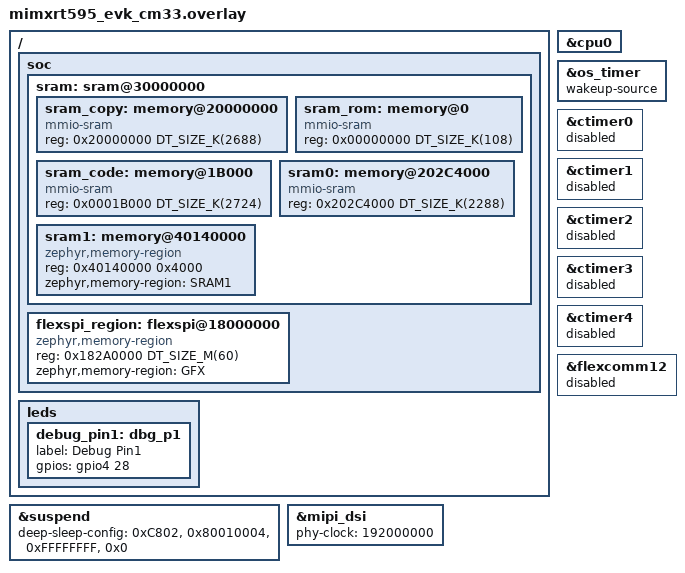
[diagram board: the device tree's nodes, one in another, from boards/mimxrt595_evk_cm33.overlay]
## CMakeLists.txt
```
# SPDX-License-Identifier: Apache-2.0

cmake_minimum_required(VERSION 3.20.0)

# If SMARTWATCH_IN_RAM_APP is defined, pull in dts and kconfig overlays for
# this feature
if (DEFINED SMARTWATCH_IN_RAM_APP)
	list(APPEND EXTRA_DTC_OVERLAY_FILE smartwatch_ram.overlay)
	list(APPEND EXTRA_CONF_FILE smartwatch_ram.conf)
	# Manually cache variable, so CMake does not warn it it unused
	set(SMARTWATCH_IN_RAM_APP CACHE BOOL "Smartwatch app in RAM")
endif()

# If SMARTWATCH_REDUCE_RAM is defined, pull in dts and kconfig overlays for
# this feature
if (DEFINED SMARTWATCH_REDUCE_RAM)
	list(APPEND EXTRA_DTC_OVERLAY_FILE reduce_ram.overlay)
	list(APPEND EXTRA_CONF_FILE reduce_ram.conf)
	# Manually cache variable, so CMake does not warn it it unused
	set(SMARTWATCH_REDUCE_RAM CACHE BOOL "Reduce SRAM utilization")
endif()

set(SHIELD g1120b0mipi)

find_package(Zephyr REQUIRED HINTS $ENV{ZEPHYR_BASE})

# Include VGLite port
add_subdirectory(vglite-port)

FILE(GLOB app_sources src/*.c)

if (DEFINED CONFIG_SMARTWATCH_PVT_SENSOR)
        set(LIB_DIR  ${CMAKE_CURRENT_SOURCE_DIR}/../../../modules/hal/appswpacks-dvs-pvt-sensor/dvs_pvt_sensor/app)
        add_library(libpvt STATIC IMPORTED GLOBAL)
        set_target_properties(libpvt PROPERTIES IMPORTED_LOCATION ${LIB_DIR}/evkmimxrt595/pvt_lib/libpvt.a)
        target_link_libraries(app PUBLIC libpvt)
        include_directories(app ${LIB_DIR}/common/pvt_lib)
        include_directories(app ${LIB_DIR}/evkmimxrt595/pvt_lib)
        include_directories(app src/PVT)
        FILE(GLOB pvt_sources src/PVT/*.c)
        list(APPEND app_sources ${pvt_sources})
      endif()

if (DEFINED CONFIG_LVGL)
        project(lvgl)

 	set(UI_PATH UI_SW)

        include_directories(app src/${UI_PATH})
        include_directories(app src/${UI_PATH}/custom)
        include_directories(app src/${UI_PATH}/generated)
        include_directories(app src/${UI_PATH}/generated/guider_customer_fonts)
        include_directories(app src/${UI_PATH}/generated/guider_fonts)
        include_directories(app src/${UI_PATH}/generated/images)

	FILE(GLOB gfx_sources src/${UI_PATH}/*.c src/${UI_PATH}/generated/*.c src/${UI_PATH}/generated/guider_fonts/*.c src/${UI_PATH}/generated/guider_customer_fonts/*.c src/${UI_PATH}/generated/images/*.c src/${UI_PATH}/custom/*.c)
	list(APPEND app_sources ${gfx_sources})

  add_library(libLogos STATIC IMPORTED GLOBAL)
  set_target_properties(libLogos PROPERTIES IMPORTED_LOCATION
      ${CMAKE_CURRENT_SOURCE_DIR}/src/${UI_PATH}/generated/images/logos_lib/libLogos.a)
  target_link_libraries(app PUBLIC libLogos)
endif()

# Relocate GFX data into a FlexSPI region. This is required because not
# all assets for the demo can fit in SRAM.
set(gfx_path src/${UI_PATH})
if(NOT CONFIG_SMARTWATCH_IN_RAM_DIGITAL_SCREEN)
  zephyr_code_relocate(FILES
    ${gfx_path}/generated/images/lv_font_Montserrat_Light_40.c
    ${gfx_path}/generated/images/ui_font_medium_font.c
    ${gfx_path}/generated/images/ui_font_number_bold.c
    ${gfx_path}/generated/images/ui_font_number_light.c
    ${gfx_path}/generated/images/ui_img_icn_flash_png.c
    ${gfx_path}/generated/images/ui_img_icn_message_png.c
    ${gfx_path}/generated/images/ui_img_icn_sport_png.c
    ${gfx_path}/generated/images/ui_img_icn_weather_1_png.c
    ${gfx_path}/generated/images/ui_img_img_bg_digital_png.c
    ${gfx_path}/generated/images/ui_img_img_clock_shadow_png.c
    ${gfx_path}/generated/images/ui_img_img_menu_png.c
    ${gfx_path}/generated/images/ui_img_img_nxp_png.c
    ${gfx_path}/generated/images/ui_img_text_message_png.c
    ${gfx_path}/generated/images/ui_img_text_sport_png.c
    LOCATION GFX_RODATA NOCOPY)
endif()

zephyr_code_relocate(FILES
  ${gfx_path}/generated/images/ui_font_big_font.c
  ${gfx_path}/generated/images/ui_font_small_font.c
  ${gfx_path}/generated/images/ui_img_icn_home_png.c
  ${gfx_path}/generated/images/ui_img_icn_small_burn_png.c
  ${gfx_path}/generated/images/ui_img_icn_small_pos_png.c
  ${gfx_path}/generated/images/ui_img_icn_small_pulse_png.c
  ${gfx_path}/generated/images/ui_img_icn_small_time_png.c
  ${gfx_path}/generated/images/ui_img_icn_small_weather_1_png.c
  ${gfx_path}/generated/images/ui_img_icn_small_weather_2_png.c
  ${gfx_path}/generated/images/ui_img_icn_small_weather_3_png.c
  ${gfx_path}/generated/images/ui_img_img_arrow_left_png.c
  ${gfx_path}/generated/images/ui_img_img_arrow_right_png.c
  ${gfx_path}/generated/images/ui_img_icn_audio_back_png.c
  ${gfx_path}/generated/images/ui_img_icn_audio_next_png.c
  ${gfx_path}/generated/images/ui_img_icn_audio_play_png.c
  ${gfx_path}/generated/images/ui_img_icn_audio_rnd_png.c
  ${gfx_path}/generated/images/ui_img_img_audio_album_png.c
  ${gfx_path}/generated/images/ui_img_img_bg_2_png.c
  ${gfx_path}/generated/images/ui_img_img_bg_analog_png.c
  ${gfx_path}/generated/images/ui_img_img_bg_health_png.c
  ${gfx_path}/generated/images/ui_img_img_clockwise_hour_png.c
  ${gfx_path}/generated/images/ui_img_img_clockwise_min_png.c
  ${gfx_path}/generated/images/ui_img_img_clockwise_sec_png.c
  ${gfx_path}/generated/images/ui_img_img_cloud_png.c
  ${gfx_path}/generated/images/ui_img_img_ekg_png.c
  ${gfx_path}/generated/images/ui_img_img_header_bg_png.c
  ${gfx_path}/generated/images/ui_img_img_header_bg_shadow_png.c
  ${gfx_path}/generated/images/ui_img_img_heart_png.c
  ${gfx_path}/generated/images/ui_img_img_nxp_logo_big_png.c
  ${gfx_path}/generated/images/ui_img_img_pause_png.c
  ${gfx_path}/generated/images/ui_img_img_squareline_png.c
  ${gfx_path}/generated/images/ui_img_img_sun_png.c
  ${gfx_path}/generated/images/ui_img_text_audio_volume_png.c
  ${gfx_path}/generated/images/ui_img_text_home_png.c
  ${gfx_path}/generated/images/ui_img_text_select_png.c
  ${gfx_path}/generated/images/ui_img_text_start_stop_png.c
  ${gfx_path}/generated/images/_coursewrkwavesfeb_dribbble_392x392.c
  ${gfx_path}/generated/images/_icn_weather_2_41x38.c
  ${gfx_path}/generated/images/_icn_weather_3_41x38.c
  ${gfx_path}/generated/images/_img_clockwise_hourLP_18x98.c
  ${gfx_path}/generated/images/_img_clockwise_minLP_18x157.c
  ${gfx_path}/generated/images/_img_clockwise_secLP_31x180.c
  ${gfx_path}/generated/images/_img_cloud_2_586x147.c
  ${gfx_path}/generated/images/_img_nxpLP_65x23.c
  ${gfx_path}/generated/images/_Zephyr_RTOS_logo_118x57.c
  LOCATION GFX_RODATA NOCOPY)

# Relocate SDMA firmware back to flash, as the driver copies it to RAM
zephyr_code_relocate(FILES
  ${ZEPHYR_BASE}/../modules/hal/nxp/mcux/mcux-sdk/drivers/smartdma/fsl_smartdma.c
  LOCATION GFX_RODATA NOCOPY)

# The following snippet modifies the objcopy relocate command the build system
# will run to relocate the built ELF file, so that the GFX section will not
# be relocated. When combined with the zephyr_code_relocate macro, this will
# result in the GFX RODATA section being relocated to flash, and not
# affecting the total image size. This means that the ROM will not attempt
# to copy the GFX data to SRAM, and it can be read directly from FlexSPI.
if(CONFIG_BUILD_OUTPUT_ADJUST_LMA)
  math(EXPR adjustment "${CONFIG_BUILD_OUTPUT_ADJUST_LMA}" OUTPUT_FORMAT DECIMAL)
  set(excluded_sections
	  ".gfx_rodata_reloc")
  set(lma_adjust --change-section-lma *+${adjustment})
  foreach(section ${excluded_sections})
    list(APPEND lma_adjust --change-section-lma !${section}+1)
  endforeach()
  set_property(TARGET bintools PROPERTY elfconvert_flag_lma_adjust ${lma_adjust})
endif()

target_sources(app PRIVATE ${app_sources})
```

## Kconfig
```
# Copyright 2023 NXP
# SPDX-License-Identifier: Apache-2.0

# Source Kconfig file from VGLite port
rsource "vglite-port/Kconfig"

# Config options for SmartWatch app

config SMARTWATCH_IN_RAM_APP
	bool "Move all code and non-LVGL rodata to internal SRAM"
	default n

config SMARTWATCH_IN_RAM_DIGITAL_SCREEN
	bool "Place all data and assets for the Digital Watch screen in SRAM"
	default n
	depends on LVGL && SMARTWATCH_IN_RAM_APP

config SMARTWATCH_REDUCE_RAM
	bool "minimizes SRAM used by application"
	default n

config SMARTWATCH_PVT_SENSOR
	bool "Enable PVT Sensor to reduce VDDCORE voltage and reduce power"
	default n
	select EVENTS
	# prebuilt lippvt.a uses VFP arguments, need to build app with CONFIG_FPU
	select FPU

config SMARTWATCH_FOR_MEASUREMENTS
	bool "When measuring power consumption, helps keep measurements consistent"
	default n

if SMARTWATCH_IN_RAM_APP

	FLEXSPI_PATH:=$(dt_nodelabel_path,flexspi)
	SRAM_PATH:=$(dt_nodelabel_path,sram_code)
	FLEXSPI_BASE:=$(dt_node_reg_addr_hex,$(FLEXSPI_PATH),1)
	SRAM_BASE:=$(dt_node_reg_addr_hex,$(SRAM_PATH))

	# Adjust the LMA of the output file to reside in FlexSPI, so that the
	# image will be loaded there. The ROM bootloader will then load the
	# application into internal SRAM
	config BUILD_OUTPUT_ADJUST_LMA
		default "$(FLEXSPI_BASE)-$(SRAM_BASE)"

endif # SMARTWATCH_IN_RAM_APP

config LV_MEM_SIZE_KILOBYTES
	default 64 if SMARTWATCH_REDUCE_RAM
	default 128

config VGLITE_HEAP_SIZE
	default 0x8000 if SMARTWATCH_REDUCE_RAM

source "Kconfig.zephyr"
```

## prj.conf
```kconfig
CONFIG_MAIN_STACK_SIZE=4096
CONFIG_IDLE_STACK_SIZE=1024
CONFIG_SYSTEM_WORKQUEUE_STACK_SIZE=2048
CONFIG_BUILD_OUTPUT_HEX=y
CONFIG_DISPLAY=y
CONFIG_FLEXCOMM0_CLK_SRC_FRO=y
CONFIG_MIPI_DPHY_CLK_SRC_FRO=y

# LVGL
CONFIG_LVGL=y
CONFIG_LV_DISP_DEF_REFR_PERIOD=17
CONFIG_LV_DISP_ROT_MAX_BUF=40960
CONFIG_LV_Z_MEM_POOL_NUMBER_BLOCKS=8
#CONFIG_LV_MEM_CUSTOM=y
CONFIG_LV_USE_LOG=y
CONFIG_LV_USE_LABEL=y
CONFIG_LV_USE_BTN=y
CONFIG_LV_USE_IMG=y
#CONFIG_LV_USE_ARC=y
CONFIG_LV_FONT_MONTSERRAT_14=y
CONFIG_LV_FONT_FMT_TXT_LARGE=y
CONFIG_LV_USE_GPU_NXP_VG_LITE=y
CONFIG_LV_Z_DOUBLE_VDB=n
CONFIG_LV_Z_FLUSH_THREAD=n

#Shell
CONFIG_SHELL=y

# Power management
CONFIG_PM=y
CONFIG_PM_DEVICE=y
CONFIG_SMARTWATCH_PVT_SENSOR=n

# Log
CONFIG_LOG=n
#CONFIG_DISPLAY_LOG_LEVEL_ERR=y

# Debugging and System View
#CONFIG_NO_OPTIMIZATIONS=y - Display does not work if optimizations disabled
#CONFIG_DEBUG_OPTIMIZATIONS=y
CONFIG_DEBUG_THREAD_INFO=y
CONFIG_INIT_STACKS=y
CONFIG_THREAD_STACK_INFO=y
CONFIG_TRACING=y
CONFIG_TRACING_THREAD_STACK_SIZE=2048

# Optimize Power by moving from flash to SRAM
CONFIG_SMARTWATCH_IN_RAM_DIGITAL_SCREEN=n

# Make sure we always can access flexSPI data
CONFIG_FLASH_MCUX_FLEXSPI_XIP=y

# For taking power measurements, to keep more consistent
CONFIG_SMARTWATCH_FOR_MEASUREMENTS=n
```

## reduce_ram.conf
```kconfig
# Copyright 2023 NXP
# SPDX-License-Identifier: Apache-2.0

CONFIG_SMARTWATCH_REDUCE_RAM=y
```

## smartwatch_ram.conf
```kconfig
# Copyright 2023 NXP
# SPDX-License-Identifier: Apache-2.0

CONFIG_SMARTWATCH_IN_RAM_APP=y
```

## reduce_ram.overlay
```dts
/*
 * Copyright 2023-2024 NXP
 *
 * SPDX-License-Identifier: Apache-2.0
 */

/ {
	soc {
		sram: sram@30000000 {
			sram0: memory@202C4000 {
				/* When SMARTWATCH_REDUCE_RAM=y, can 
				 * reduce RAM size
				 */
				reg = < 0x202C4000 DT_SIZE_K(1264) >;
			};
			/* When SMARTWATCH_REDUCE_RAM=y, remaining SRAM
			 * is powered off to improve battery life
			 */
			sram_unpowered: memory@20400000 {
				compatible = "mmio-sram";
				reg = < 0x20400000 DT_SIZE_M(1) >;
			};
		};
	};
};

&suspend {
	/* Keep Powered in Deep Sleep */
	deep-sleep-config =
		/* PDSLEEPCFG0: RBBs, LPOSC, PMIC_MODE=1 */
		< 0xC802 >,
		/* PDSLEEPCFG1: SRAM_SLEEP, SDMA_SRAM, FlexSPI0_SRAM */
		< 0x80010004 >,
		/* PDSLEEPCFG2: power off some of the SRAM */
		< 0x0FFFFFF9 >,
		/* PDSLEEPCFG3: no System SRAM peripheries */
		< 0x0 >;
};
```

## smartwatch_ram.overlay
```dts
/*
 * Copyright 2023, NXP
 *
 * SPDX-License-Identifier: Apache-2.0
 */

/ {
	/*
	 * Move flash region to SRAM, so that code and rodata will be linked
	 * there instead of into FlexSPI. Note some large LVGL assets will
	 * still be located in the flash region.
	 */
	chosen {
		zephyr,flash = &sram_code;
	};
};
```

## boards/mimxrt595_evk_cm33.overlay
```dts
/*
 * Copyright 2023-2024 NXP
 *
 * SPDX-License-Identifier: Apache-2.0
 */

/ {
	soc {
		/* Use all 5MB of SRAM */
		/delete-node/ sram@30018000;
		sram: sram@30000000 {
			ranges = <
				0x00000000 0x10000000 DT_SIZE_M(5)
				0x20000000 0x30000000 DT_SIZE_M(5) >;
			#address-cells = < 0x1 >;
			#size-cells = < 0x1 >;
			sram_copy: memory@20000000 {
				compatible = "mmio-sram";
				reg = < 0x20000000 DT_SIZE_K(2688) >;
			};
			/*
			 * The first 0x1BFFF bytes of SRAM are reserved
			 * for the ROM, and it will not perform a Load-to-RAM.
			 * boot into that location. Note that the ROM headers
			 * take up 0x1000 bytes, so we can
			 * start the image location at 0x1B000.
			 */
			sram_rom: memory@0 {
				compatible = "mmio-sram";
				reg = < 0x00000000 DT_SIZE_K(108) >;
			};
			sram_code: memory@1B000 {
				compatible = "mmio-sram";
				reg = < 0x0001B000 DT_SIZE_K(2724) >;
			};
			sram0: memory@202C4000 {
				compatible = "mmio-sram";
				reg = < 0x202C4000 DT_SIZE_K(2288) >;
			};
			sram1: memory@40140000 {
				compatible = "zephyr,memory-region", "mmio-sram";
				reg = < 0x40140000 0x4000 >;
				zephyr,memory-region = "SRAM1";
			};
		};

		flexspi_region: flexspi@18000000 {
			compatible = "zephyr,memory-region";
			reg = <0x182A0000 DT_SIZE_M(60)>;
			zephyr,memory-region = "GFX";
		};
	};

	leds {
		/* For debugging:
		*	- CLKOUT, J18-p1, P2_29
		*	- dbg_p1, J28-p1, P4_28
		*/
		debug_pin1: dbg_p1 {
			label = "Debug Pin1";
			gpios = <&gpio4 28 GPIO_ACTIVE_HIGH>;
			status = "okay";
		};
	};
};

&cpu0 {
	/* Removes Deep Sleep (Suspend) option from PM subsystem */
	//cpu-power-states = < &idle >;
};

&suspend {
	/* Keep Powered in Deep Sleep */
	deep-sleep-config =
		/* PDSLEEPCFG0: RBBs, LPOSC, PMIC_MODE=1 */
		< 0xC802 >,
		/* PDSLEEPCFG1: SRAM_SLEEP, SDMA_SRAM, FlexSPI0_SRAM */
		< 0x80010004 >,
		/* PDSLEEPCFG2: keep all SRAM powered */
		< 0xFFFFFFFF >,
		/* PDSLEEPCFG3: no System SRAM peripheries */
		< 0x0 >;
};

&os_timer {
	status = "okay";
	wakeup-source;
};

/* Disable the unused CTimers */
&ctimer0 {
	status = "disabled";
};
&ctimer1 {
	status = "disabled";
};
&ctimer2 {
	status = "disabled";
};
&ctimer3 {
	status = "disabled";
};
&ctimer4 {
	status = "disabled";
};

&mipi_dsi {
	phy-clock = < 192000000 >;
};

/* Disable Flexcomm12.  PIO4_30 input has high leakage on EVK */
&flexcomm12 {
	status = "disabled";
};
```

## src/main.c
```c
/*
 * Copyright 2023-2024 NXP
 *
 * SPDX-License-Identifier: Apache-2.0
 */

#include <zephyr/device.h>
#include <zephyr/devicetree.h>
#include <zephyr/drivers/gpio.h>
#include <zephyr/kernel.h>
#include "board.h"
#include "fsl_power.h"

#ifdef CONFIG_LOG
	#define LOG_LEVEL CONFIG_LOG_DEFAULT_LEVEL
	#include <zephyr/logging/log.h>
	LOG_MODULE_REGISTER(app);
#else
	#undef  LOG_ERR
	#define LOG_ERR(...)
#endif

#ifdef CONFIG_PM
	#include <zephyr/pm/pm.h>
#endif

/*******************************************************************************
 * Definitions
 ******************************************************************************/
/* for threads */
#define THREAD_STACKSIZE	4096
#define THREAD_PRIORITY_PVT	1	/* PVT Sensor thread highest priority */
#define THREAD_PRIORITY_LVGL	2

/*******************************************************************************
 * Global Variables
 ******************************************************************************/

/*******************************************************************************
 * Prototypes
 ******************************************************************************/

#ifdef CONFIG_LVGL
	/* lvgl_thread */
	extern void lvgl_thread(void *dummy1, void *dummy2, void *dummy3);

	K_THREAD_STACK_DEFINE(lvgl_thread_stack_area, THREAD_STACKSIZE);
	static struct k_thread lvgl_thread_data;
#endif

#ifdef CONFIG_SMARTWATCH_PVT_SENSOR
	#include "PVT_Sensor.h"

	K_THREAD_STACK_DEFINE(pvt_thread_stack_area, THREAD_STACKSIZE);
	static struct k_thread pvt_thread_data;
#endif

#ifdef CONFIG_GPIO
	static struct gpio_dt_spec button_gpio = GPIO_DT_SPEC_GET_OR(
			DT_ALIAS(sw0), gpios, {0});
	static struct gpio_callback button_callback;

	static void button_isr_callback(const struct device *port,
					struct gpio_callback *cb,
					uint32_t pins)
	{
		ARG_UNUSED(port);
		ARG_UNUSED(cb);
		ARG_UNUSED(pins);
	}

	/* GPIO pins for debugging and profiling */
	#define DBG_P1 DT_NODELABEL(debug_pin1)
	const struct gpio_dt_spec dbg_p1 = GPIO_DT_SPEC_GET(DBG_P1, gpios);
#endif

#ifdef CONFIG_PM
	/* Callbacks for PM subsystem */
	static void notify_pm_state_entry(enum pm_state state)
	{
	#ifdef CONFIG_GPIO
		gpio_pin_set_dt(&dbg_p1, 0);
	#endif
	}

	static void notify_pm_state_exit(enum pm_state state)
	{
	#ifdef CONFIG_GPIO
		gpio_pin_set_dt(&dbg_p1, 1);
	#endif
	}

	static struct pm_notifier notifier = {
		.state_entry = notify_pm_state_entry,
		.state_exit = notify_pm_state_exit,
	};
#endif /* CONFIG_PM */

static void App_HW_Optimizations(void)
{
	POWER_EnablePD(kPDRUNCFG_PD_OTP);

	/* Disable unused SRAMs */
	/* DSP is not used, disable AHB access to all SRAMs */
	SYSCTL0->DSP_SRAM_ACCESS_DISABLE = 0xFFFFFFFFU;

#ifdef CONFIG_SMARTWATCH_REDUCE_RAM
	#if (DT_REG_ADDR(DT_NODELABEL(sram_unpowered)) == 0x30300000)
		/* 3MB of SRAM used, power down remaining 2MB and reserved SRAM_ROM */
		uint32_t sram_pd_mask = 0xFF000006U;
	#elif (DT_REG_ADDR(DT_NODELABEL(sram_unpowered)) == 0x30400000)
		/* 4MB of SRAM used, power down remaining 3MB and reserved SRAM_ROM */
		uint32_t sram_pd_mask = 0xF0000006U;
	#else
		#error Amount of SRAM to power off is not configured
	#endif

	SYSCTL0->PDRUNCFG2		 = sram_pd_mask;
	SYSCTL0->PDRUNCFG3		 = sram_pd_mask;
	PMC->CTRL |= PMC_CTRL_APPLYCFG_MASK;
	SYSCTL0->AHB_SRAM_ACCESS_DISABLE = sram_pd_mask;
	SYSCTL0->AXI_SRAM_ACCESS_DISABLE = sram_pd_mask;
#endif /* CONFIG_SMARTWATCH_REDUCE_RAM */
}

int main(void)
{
	int32_t ret;

	printk("SmartWatch Demo\r\n");

#ifdef CONFIG_PM
	pm_notifier_register(&notifier);
#endif
	ret = power_manager_set_profile(POWER_PROFILE_FRO192M_900MV);
	if (ret) {
		printk("ERROR: power_manager_set_profile() returned %d\r\n", ret);
		while(1);
	}

	App_HW_Optimizations();
	printk("Power Profile changed to POWER_PROFILE_FRO192M_900MV\r\n");

#ifdef CONFIG_GPIO
	int err;

	if (device_is_ready(button_gpio.port)) {
		err = gpio_pin_configure_dt(&button_gpio, GPIO_INPUT);
		if (err) {
			LOG_ERR("failed to configure button gpio: %d", err);
			return err;
		}

		gpio_init_callback(&button_callback, button_isr_callback,
					BIT(button_gpio.pin));

		err = gpio_add_callback(button_gpio.port, &button_callback);
		if (err) {
			LOG_ERR("failed to add button callback: %d", err);
			return err;
		}

		err = gpio_pin_interrupt_configure_dt(&button_gpio,
						      GPIO_INT_EDGE_TO_ACTIVE);
		if (err) {
			LOG_ERR("failed to enable button callback: %d", err);
			return err;
		}
	}

	if (device_is_ready(dbg_p1.port))
	{
		err = gpio_pin_configure_dt(&dbg_p1, GPIO_OUTPUT_ACTIVE);
		if (err) {
			LOG_ERR("failed to configure dbg_p1 gpio: %d", err);
			return err;
		}
	}
#endif

#ifdef CONFIG_SMARTWATCH_PVT_SENSOR
	set_PVT_max_voltage(VDDCORE_192MHZ_SAFE_VMIN);
	set_PVT_min_voltage(VDDCORE_MIPI_VMIN);

	/* Create pvt_thread */
	k_thread_create(&pvt_thread_data, pvt_thread_stack_area,
			K_THREAD_STACK_SIZEOF(pvt_thread_stack_area),
			pvt_thread, NULL, NULL, NULL,
			THREAD_PRIORITY_PVT, 0, K_FOREVER);
	k_thread_name_set(&pvt_thread_data, "pvt_thread");
	k_thread_start(&pvt_thread_data);
#endif

#ifdef CONFIG_LVGL
	/* Create lvgl_thread */
	k_thread_create(&lvgl_thread_data, lvgl_thread_stack_area,
			K_THREAD_STACK_SIZEOF(lvgl_thread_stack_area),
			lvgl_thread, NULL, NULL, NULL,
			THREAD_PRIORITY_LVGL, 0, K_FOREVER);
	k_thread_name_set(&lvgl_thread_data, "lvgl_thread");
	k_thread_start(&lvgl_thread_data);
#else /* CONFIG_LVGL not defined */
	while (1)
	{
		k_sleep(K_MSEC(1000));
	}
#endif /* CONFIG_LVGL */
}

void SystemInitHook(void)
{
	/* Initialize FlexSPI cache if not already */
	if (CACHE64_POLSEL0->POLSEL == 0U) /* set CAHCHE64 if not configured */
	{
		/* set command to invalidate all ways and write GO bit to initiate command */
		CACHE64_CTRL0->CCR = CACHE64_CTRL_CCR_INVW1_MASK | CACHE64_CTRL_CCR_INVW0_MASK;
		CACHE64_CTRL0->CCR |= CACHE64_CTRL_CCR_GO_MASK;
		/* Wait until the command completes */
		while ((CACHE64_CTRL0->CCR & CACHE64_CTRL_CCR_GO_MASK) != 0U)
		{
		}
		/* Enable cache, enable write buffer */
		CACHE64_CTRL0->CCR = (CACHE64_CTRL_CCR_ENWRBUF_MASK | CACHE64_CTRL_CCR_ENCACHE_MASK);

		/* Set whole FlexSPI0 space to write through. */
		CACHE64_POLSEL0->REG0_TOP = 0x07FFFC00U;
		CACHE64_POLSEL0->REG1_TOP = 0x0U;
		CACHE64_POLSEL0->POLSEL   = 0x1U;

		__ISB();
		__DSB();
	}
}
```

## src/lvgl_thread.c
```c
/*
 * Copyright (c) 2018 Jan Van Winkel <jan.van_winkel@dxplore.eu>
 * Copyright 2023-2024 NXP
 *
 * Originated from:
 * https://github.com/zephyrproject-rtos/zephyr/blob/main/samples/subsys/display/lvgl/src/main.c
 * SPDX-License-Identifier: Apache-2.0
 */

#ifdef CONFIG_LVGL

#include <zephyr/device.h>
#include <zephyr/devicetree.h>
#include <zephyr/kernel.h>
#include <vg_lite.h>

#ifdef CONFIG_SHELL
	#include <zephyr/shell/shell.h>

	static int time_change(const struct shell *shell, int32_t argc, char **argv);
#endif

#include <lvgl.h>
#include <zephyr/drivers/display.h>
#include "../../../../../modules/lib/gui/lvgl/src/core/lv_disp.h"

#include <screen_setup.h>
#include <gui_guider.h>
#include <events_init.h>

#include <animation.h>
#include <ui_helpers.h>

#include <ui_Weather.h>
#include <ui_SportAPI.h>
#include <ui_Watch_Face.h>
#include <ui_Music.h>
#include <ui_EKG.h>

#define MAIN_SCREENS 5
#define SUB_SCREENS 3

/**********************************************************************
 * Global Variables
 **********************************************************************/
lv_ui guider_ui;
int16_t MainScreenCnt = 0;
int16_t SubScreenCnt = 0;
lv_obj_t *ptrScreen[MAIN_SCREENS][SUB_SCREENS];
int16_t task_delay = 1;

/**********************************************************************
 * Prototypes
 **********************************************************************/
void ChangeScreen(lv_dir_t Dir);
static void IdentifyScreens (void);
void changedirectory(void);
void update_lvtask_delay(void);
void update_lvtask_delay_fast(void);

/*******************************************************************************
 * Global Variables
 ******************************************************************************/

/*******************************************************************************
 * Prototypes
 ******************************************************************************/

K_SEM_DEFINE(touch_sem, 0, 1);

#ifdef CONFIG_GPIO
	#include <zephyr/drivers/gpio.h>

	static void touch_timer_expired(struct k_timer *timer);
	K_TIMER_DEFINE(touch_isr_enable, touch_timer_expired, NULL);

	/* Display touch INT pin */
	#define TOUCH_NODE DT_NODELABEL(ft3267_g1120b0mipi)
	const struct gpio_dt_spec touch_pin = GPIO_DT_SPEC_GET(TOUCH_NODE, int_gpios);
	struct gpio_callback touch_pin_cb;
	static void touch_pin_handler(const struct device *dev,
					struct gpio_callback *cb, uint32_t pins)
	{
		/*
		 * ------------------- WORKAROUND ---------------------------
		 * The FT3267 touch IC pulls the INT pin low continuously for
		 * ~5 ms after a touch input. The RT500 GPIO interrupt has
		 * a limitation where the GPIO interrupt only works in
		 * LEVEL mode when entering deep sleep. Since the GPIO
		 * driver reconfigures GPIO pins with edge mode to use
		 * level interrupts when entering sleep, the part will be
		 * awoken continuously during these 5 ms.

		 * To fix this, we disable the touch interrupt and set a 6ms
		 * kernel timer. When the timer expires, we will enable the
		 * touch interrupt again.
		 */
		gpio_pin_interrupt_configure_dt(&touch_pin, GPIO_INT_DISABLE);
		k_timer_start(&touch_isr_enable, K_MSEC(6), K_NO_WAIT);
		/* Signal to the application that touch data was sent */
		k_sem_give(&touch_sem);
	}


	static void touch_timer_expired(struct k_timer *timer) {
		gpio_pin_interrupt_configure_dt(&touch_pin,
			GPIO_INT_EDGE_TO_ACTIVE |
			GPIO_INT_WAKEUP);
	}
#endif

void changedirectory(void)
{
	 MainScreenCnt = 0;
	 SubScreenCnt = 0;
}

void changedirectoryMusic(void)
{
	lv_scr_load(guider_ui.ui_S11_Music);
	MainScreenCnt = 3;
	SubScreenCnt = 0;
}

void update_lvtask_delay(void)
{
	task_delay = 1000;
}

void update_lvtask_delay_fast(void)
{
	task_delay = 5;
}


void changedirectoryTime(void)
{
	lv_scr_load(guider_ui.ui_S1_Watch_Digital);
	MainScreenCnt = 0;
	SubScreenCnt = 0;
}

void changedirectoryWeather(void)
{
	lv_scr_load(guider_ui.ui_S5_Weather);
	MainScreenCnt = 1;
	SubScreenCnt = 0;
}

void changedirectoryFit(void)
{
	lv_scr_load(guider_ui.ui_S9_Sport);
	MainScreenCnt = 2;
	SubScreenCnt = 0;
}

void changedirectoryHeart(void)
{
	lv_scr_load(guider_ui.ui_S24_EKG);
	MainScreenCnt = 4;
	SubScreenCnt = 0;
}

void ChangeScreen(lv_dir_t Dir)
{
	uint8_t main_val=MainScreenCnt;
	uint8_t sub_val=SubScreenCnt;

	if(Dir == LV_DIR_TOP)
	{

		MainScreenCnt++;

		if((ptrScreen[MainScreenCnt][SubScreenCnt] == NULL) || (MainScreenCnt >= MAIN_SCREENS))
		{
			MainScreenCnt = 0;
			SubScreenCnt = 0;

		}
	}
	else if(Dir == LV_DIR_BOTTOM)
	{
		MainScreenCnt--;
		if((ptrScreen[MainScreenCnt][SubScreenCnt] == NULL) || (MainScreenCnt < 0))
		{
			MainScreenCnt = MAIN_SCREENS - 1;
			SubScreenCnt = 0;
		}
	}
	else if(Dir == LV_DIR_LEFT)
	{
		SubScreenCnt++;
		if((ptrScreen[MainScreenCnt][SubScreenCnt] == NULL) || (SubScreenCnt >= SUB_SCREENS))
		{
			SubScreenCnt = 0;
		}
	}
	else if(Dir == LV_DIR_RIGHT)
	{
		if((ptrScreen[MainScreenCnt][SubScreenCnt - 1] != NULL) && ((SubScreenCnt - 1) >= 0))
		{
			SubScreenCnt--;
		}
	}
	else
	{
		/* Do nothing, no valid direction */
	}

	if(main_val!=MainScreenCnt||sub_val!=SubScreenCnt)
	{
		lv_scr_load_anim(ptrScreen[MainScreenCnt][SubScreenCnt], LV_SCR_LOAD_ANIM_FADE_OUT, 10, 0, false);
	}
}

static void IdentifyScreens(void)
{
	ptrScreen[0][0] = guider_ui.ui_S1_Watch_Digital;
	ptrScreen[0][1] = guider_ui.ui_S2_Watch_Analog;
	ptrScreen[1][0] = guider_ui.ui_S5_Weather;
	ptrScreen[2][0] = guider_ui.ui_S9_Sport;
	ptrScreen[3][0] = guider_ui.ui_S24_EKG ;
	ptrScreen[4][0] = guider_ui.ui_S11_Music;
	ptrScreen[0][2] = guider_ui.ui_SLowPower;
}

#ifdef CONFIG_SHELL
static int time_change(const struct shell *shell, int32_t argc, char **argv){

	uint16_t u16Hours = ((int16_t)atoi(argv[1]));
	uint16_t u16Minutes = ((int8_t)atoi(argv[2]));

	updateTIMERS(u16Minutes, u16Hours);
	if(u16Hours > 23 || u16Minutes > 59)
	{
	} else
	{
		lv_label_set_text(guider_ui.ui_Label_Hour, argv[1]);
		lv_label_set_text(guider_ui.ui_Label_Minute, argv[2]);
	}

	return 0;
}

SHELL_CMD_REGISTER(time, NULL, "Toggle LED command", time_change);
#endif /* CONFIG_SHELL */

#define VG_LITE_COMMAND_BUFFER_SIZE                     (128 << 10) /* 128 KB */

/* Default tessellation window width and height, in pixels */
#define DEFAULT_VG_LITE_TW_WIDTH                        128 /* pixels */
#define DEFAULT_VG_LITE_TW_HEIGHT                       128 /* pixels */

void lvgl_thread(void *dummy1, void *dummy2, void *dummy3)
{
	ARG_UNUSED(dummy1);
	ARG_UNUSED(dummy2);
	ARG_UNUSED(dummy3);

#ifdef CONFIG_GPIO
	if (device_is_ready(touch_pin.port)) {
		gpio_init_callback(&touch_pin_cb, touch_pin_handler,
				BIT(touch_pin.pin));
		gpio_add_callback(touch_pin.port, &touch_pin_cb);

	}
#endif

	const struct device *display_dev;
	int ret;

#ifdef CONFIG_LV_USE_GPU_NXP_VG_LITE
	/*
	 * We must call vg_lite_init() from any thread using the GPU. Since
	 * we render on the LVGL thread, call vg_lite_init() here
	 */
	if (vg_lite_init(DEFAULT_VG_LITE_TW_WIDTH, DEFAULT_VG_LITE_TW_HEIGHT) != VG_LITE_SUCCESS) {
	    printk("VGLite init error\n");
	    return;
	}

	if (vg_lite_set_command_buffer_size(VG_LITE_COMMAND_BUFFER_SIZE) != VG_LITE_SUCCESS) {
	    printk("VGLite set command buffer fail\n");
	    return;
	}

#endif

	display_dev = DEVICE_DT_GET(DT_CHOSEN(zephyr_display));
	if (!device_is_ready(display_dev)) {
		printk("Device not ready, aborting test");
		return;
	}

	lv_task_handler();
	display_blanking_off(display_dev);

	complete_set();
	lv_scr_load(guider_ui.ui_S0_Splash);
	IdentifyScreens();

	while (1)
	{
		/* Take from the touch interrupt semaphore.
			* We timeout after 1000ms, as we still want to
			* refresh the display at least this often.
			*/

		ret = k_sem_take(&touch_sem, K_MSEC(task_delay));
		if (ret == -EAGAIN) {
			/* Semaphore timed out. Without any new
				* touch data, we only need to refresh the
				* display once.
				*/

			if(ptrScreen[MainScreenCnt][SubScreenCnt] == guider_ui.ui_S2_Watch_Analog || ptrScreen[MainScreenCnt][SubScreenCnt] == guider_ui.ui_S1_Watch_Digital || ptrScreen[MainScreenCnt][SubScreenCnt] == guider_ui.ui_SLowPower){
				update_lvtask_delay();
			}

			lv_task_handler();
		} else
		{
			update_lvtask_delay_fast();
		}
	}
}

#endif /* CONFIG_LVGL*/
```
